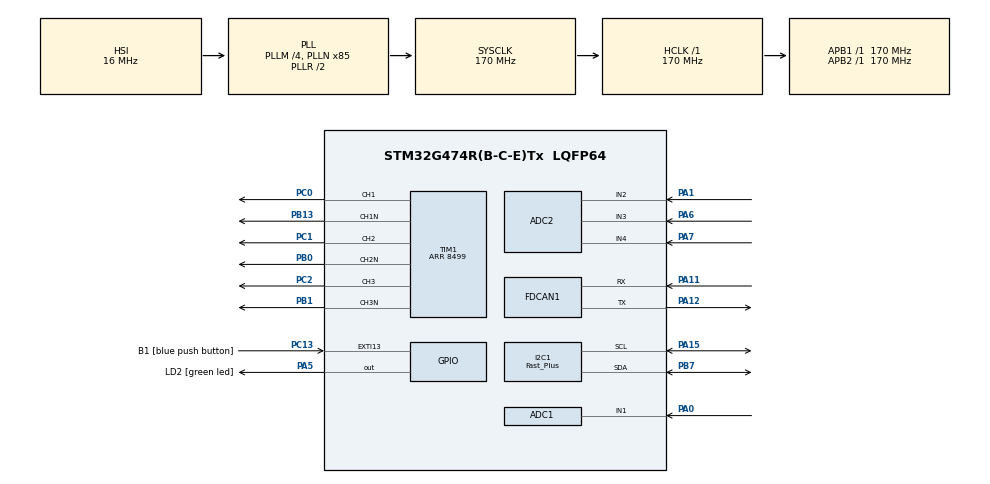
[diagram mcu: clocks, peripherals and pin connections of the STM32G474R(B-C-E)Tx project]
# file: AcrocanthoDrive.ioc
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ADC1.EnableInjectedConversion=ENABLE
ADC1.EnableRegularConversion=DISABLE
ADC1.ExternalTrigInjecConv=ADC_EXTERNALTRIGINJEC_T1_TRGO
ADC1.InjNumberOfConversion=1
ADC1.InjectedChannel-1\#ChannelInjectedConversion=ADC_CHANNEL_1
ADC1.InjectedOffsetNumber-1\#ChannelInjectedConversion=ADC_OFFSET_NONE
ADC1.InjectedRank-1\#ChannelInjectedConversion=1
ADC1.InjectedSamplingTime-1\#ChannelInjectedConversion=ADC_SAMPLETIME_2CYCLES_5
ADC1.Mode=ADC_DUALMODE_INJECSIMULT
ADC1.Rank1_Channel=ADC_CHANNEL_1
ADC1.master=1
ADC2.EOCSelection=ADC_EOC_SEQ_CONV
ADC2.EnableInjectedConversion=ENABLE
ADC2.EnableRegularConversion=DISABLE
ADC2.InjNumberOfConversion=3
ADC2.InjectedChannel-3\#ChannelInjectedConversion=ADC_CHANNEL_2
ADC2.InjectedChannel-4\#ChannelInjectedConversion=ADC_CHANNEL_3
ADC2.InjectedChannel-5\#ChannelInjectedConversion=ADC_CHANNEL_4
ADC2.InjectedOffsetNumber-3\#ChannelInjectedConversion=ADC_OFFSET_NONE
ADC2.InjectedOffsetNumber-4\#ChannelInjectedConversion=ADC_OFFSET_NONE
ADC2.InjectedOffsetNumber-5\#ChannelInjectedConversion=ADC_OFFSET_NONE
ADC2.InjectedRank-3\#ChannelInjectedConversion=1
ADC2.InjectedRank-4\#ChannelInjectedConversion=2
ADC2.InjectedRank-5\#ChannelInjectedConversion=3
ADC2.InjectedSamplingTime-3\#ChannelInjectedConversion=ADC_SAMPLETIME_2CYCLES_5
ADC2.InjectedSamplingTime-4\#ChannelInjectedConversion=ADC_SAMPLETIME_2CYCLES_5
ADC2.InjectedSamplingTime-5\#ChannelInjectedConversion=ADC_SAMPLETIME_2CYCLES_5
ADC2.Mode=ADC_DUALMODE_INJECSIMULT
ADC2.Rank1_Channel=ADC_CHANNEL_2
ADC2.Rank2_Channel=ADC_CHANNEL_3
ADC2.Rank3_Channel=ADC_CHANNEL_4
Dma.I2C1_RX.0.Direction=DMA_PERIPH_TO_MEMORY
Dma.I2C1_RX.0.EventEnable=DISABLE
Dma.I2C1_RX.0.Instance=DMA1_Channel1
Dma.I2C1_RX.0.MemDataAlignment=DMA_MDATAALIGN_BYTE
Dma.I2C1_RX.0.MemInc=DMA_MINC_ENABLE
Dma.I2C1_RX.0.Mode=DMA_NORMAL
Dma.I2C1_RX.0.PeriphDataAlignment=DMA_PDATAALIGN_BYTE
Dma.I2C1_RX.0.PeriphInc=DMA_PINC_DISABLE
Dma.I2C1_RX.0.Polarity=HAL_DMAMUX_REQ_GEN_RISING
Dma.I2C1_RX.0.Priority=DMA_PRIORITY_LOW
Dma.I2C1_RX.0.RequestNumber=1
Dma.I2C1_RX.0.SignalID=NONE
Dma.I2C1_RX.0.SyncEnable=DISABLE
Dma.I2C1_RX.0.SyncPolarity=HAL_DMAMUX_SYNC_NO_EVENT
Dma.I2C1_RX.0.SyncRequestNumber=1
Dma.I2C1_RX.0.SyncSignalID=NONE
Dma.I2C1_TX.1.Direction=DMA_MEMORY_TO_PERIPH
Dma.I2C1_TX.1.EventEnable=DISABLE
Dma.I2C1_TX.1.Instance=DMA1_Channel2
Dma.I2C1_TX.1.MemDataAlignment=DMA_MDATAALIGN_BYTE
Dma.I2C1_TX.1.MemInc=DMA_MINC_ENABLE
Dma.I2C1_TX.1.Mode=DMA_NORMAL
Dma.I2C1_TX.1.PeriphDataAlignment=DMA_PDATAALIGN_BYTE
Dma.I2C1_TX.1.PeriphInc=DMA_PINC_DISABLE
Dma.I2C1_TX.1.Polarity=HAL_DMAMUX_REQ_GEN_RISING
Dma.I2C1_TX.1.Priority=DMA_PRIORITY_LOW
Dma.I2C1_TX.1.RequestNumber=1
Dma.I2C1_TX.1.SignalID=NONE
Dma.I2C1_TX.1.SyncEnable=DISABLE
Dma.I2C1_TX.1.SyncPolarity=HAL_DMAMUX_SYNC_NO_EVENT
Dma.I2C1_TX.1.SyncRequestNumber=1
Dma.I2C1_TX.1.SyncSignalID=NONE
Dma.Request0=I2C1_RX
Dma.Request1=I2C1_TX
FDCAN1.CalculateBaudRateNominal=499999
FDCAN1.CalculateTimeBitNominal=2000
FDCAN1.CalculateTimeQuantumNominal=29.411764705882355
FDCAN1.DataPrescaler=5
FDCAN1.DataSyncJumpWidth=4
FDCAN1.DataTimeSeg1=12
FDCAN1.DataTimeSeg2=4
FDCAN1.FrameFormat=FDCAN_FRAME_FD_BRS
FDCAN1.NominalPrescaler=5
FDCAN1.NominalSyncJumpWidth=11
FDCAN1.NominalTimeSeg1=56
FDCAN1.NominalTimeSeg2=11
FDCAN1.ProtocolException=ENABLE
I2C1.I2C_Speed_Mode=I2C_Fast_Plus
I2C1.Timing=0x4052060F
Mcu.Family=STM32G4
Mcu.Name=STM32G474R(B-C-E)Tx
Mcu.Package=LQFP64
NVIC.ADC1_2_IRQn=true\:0\:0\:false\:false\:true\:true\:true\:true
NVIC.DMA1_Channel1_IRQn=true\:0\:0\:false\:false\:true\:false\:true\:true
NVIC.DMA1_Channel2_IRQn=true\:0\:0\:false\:false\:true\:false\:true\:true
NVIC.EXTI15_10_IRQn=true\:0\:0\:false\:false\:true\:true\:true\:true
NVIC.FDCAN1_IT0_IRQn=true\:0\:0\:false\:false\:true\:true\:true\:true
NVIC.FDCAN1_IT1_IRQn=true\:0\:0\:false\:false\:true\:true\:true\:true
NVIC.I2C1_ER_IRQn=true\:0\:0\:false\:false\:true\:true\:true\:true
NVIC.I2C1_EV_IRQn=true\:0\:0\:false\:false\:true\:true\:true\:true
NVIC.PriorityGroup=NVIC_PRIORITYGROUP_4
PA0.Mode=IN1-Single-Ended
PA0.Signal=ADC1_IN1
PA1.Mode=IN2-Single-Ended
PA1.Signal=ADC2_IN2
PA11.Mode=FDCAN_Activate
PA11.Signal=FDCAN1_RX
PA12.Mode=FDCAN_Activate
PA12.Signal=FDCAN1_TX
PA13.GPIO_Label=T_SWDIO
PA13.Signal=SYS_JTMS-SWDIO
PA14.GPIO_Label=T_SWCLK
PA14.Signal=SYS_JTCK-SWCLK
PA15.Mode=I2C
PA15.Signal=I2C1_SCL
PA2.GPIO_Label=LPUART1_TX [STLINKV3E_VCP_RX]
PA2.Signal=LPUART1_TX
PA3.GPIO_Label=LPUART1_RX [STLINKV3E_VCP_TX]
PA3.Signal=LPUART1_RX
PA5.GPIO_Label=LD2 [green led]
PA5.Signal=GPIO_Output
PA6.Mode=IN3-Single-Ended
PA6.Signal=ADC2_IN3
PA7.Mode=IN4-Single-Ended
PA7.Signal=ADC2_IN4
PB0.Mode=PWM Generation2 CH2 CH2N
PB0.Signal=TIM1_CH2N
PB1.Mode=PWM Generation3 CH3 CH3N
PB1.Signal=TIM1_CH3N
PB13.Mode=PWM Generation1 CH1 CH1N
PB13.Signal=TIM1_CH1N
PB3.GPIO_Label=T_SWO
PB3.Signal=SYS_JTDO-SWO
PB7.Mode=I2C
PB7.Signal=I2C1_SDA
PC0.Signal=S_TIM1_CH1
PC1.Signal=S_TIM1_CH2
PC13.GPIO_Label=B1 [blue push button]
PC13.Signal=GPXTI13
PC14-OSC32_IN.GPIO_Label=RCC_OSC32_IN
PC14-OSC32_IN.Signal=RCC_OSC32_IN
PC15-OSC32_OUT.GPIO_Label=RCC_OSC32_OUT
PC15-OSC32_OUT.Signal=RCC_OSC32_OUT
PC2.Signal=S_TIM1_CH3
PF0-OSC_IN.GPIO_Label=RCC_OSC_IN
PF0-OSC_IN.Signal=RCC_OSC_IN
PF1-OSC_OUT.GPIO_Label=RCC_OSC_OUT
PF1-OSC_OUT.Signal=RCC_OSC_OUT
ProjectManager.HeapSize=0x200
ProjectManager.StackSize=0x400
ProjectManager.TargetToolchain=STM32CubeIDE
RCC.ADC12Freq_Value=170000000
RCC.ADC345Freq_Value=170000000
RCC.AHBFreq_Value=170000000
RCC.APB1Freq_Value=170000000
RCC.APB1TimFreq_Value=170000000
RCC.APB2Freq_Value=170000000
RCC.APB2TimFreq_Value=170000000
RCC.CortexFreq_Value=170000000
RCC.EXTERNAL_CLOCK_VALUE=12288000
RCC.HCLKFreq_Value=170000000
RCC.HSE_VALUE=24000000
RCC.HSI48_VALUE=48000000
RCC.HSI_VALUE=16000000
RCC.LSE_VALUE=32768
RCC.PLLM=RCC_PLLM_DIV4
RCC.PLLN=85
RCC.RTCClockSelection=RCC_RTCCLKSOURCE_LSE
RCC.SYSCLKFreq_VALUE=170000000
RCC.SYSCLKSource=RCC_SYSCLKSOURCE_PLLCLK
RCC.USBFreq_Value=170000000
RCC.VCOOutputFreq_Value=340000000
SH.S_TIM1_CH1.0=TIM1_CH1,PWM Generation1 CH1 CH1N
SH.S_TIM1_CH2.0=TIM1_CH2,PWM Generation2 CH2 CH2N
SH.S_TIM1_CH3.0=TIM1_CH3,PWM Generation3 CH3 CH3N
TIM1.AutoReloadPreload=TIM_AUTORELOAD_PRELOAD_ENABLE
TIM1.Channel-PWM\ Generation1\ CH1\ CH1N=TIM_CHANNEL_1
TIM1.Channel-PWM\ Generation2\ CH2\ CH2N=TIM_CHANNEL_2
TIM1.Channel-PWM\ Generation3\ CH3\ CH3N=TIM_CHANNEL_3
TIM1.CounterMode=TIM_COUNTERMODE_CENTERALIGNED1
TIM1.DeadTime=20
TIM1.DeadTimePreload=ENABLE
TIM1.PeriodNoDither=8499
TIM1.RepetitionCounter=1
TIM1.TIM_MasterOutputTrigger=TIM_TRGO_UPDATE
TIM1.TIM_MasterOutputTrigger2=TIM_TRGO2_UPDATE
TIM1.TIM_MasterSlaveMode=TIM_MASTERSLAVEMODE_ENABLE
VP_CORDIC_VS_CORDIC.Mode=CORDIC_Activate
VP_SYS_VS_DBSignals.Mode=DisableDeadBatterySignals
board=NUCLEO-G474RE

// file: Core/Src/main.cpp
/* USER CODE BEGIN Header */
/**
  ******************************************************************************
  * @file           : main.c
  * @brief          : Main program body
  ******************************************************************************
  * @attention
  *
  * Copyright (c) 2024 STMicroelectronics.
  * All rights reserved.
  *
  * This software is licensed under terms that can be found in the LICENSE file
  * in the root directory of this software component.
  * If no LICENSE file comes with this software, it is provided AS-IS.
  *
  ******************************************************************************
  */
/* USER CODE END Header */
#include "main.h"

/* USER CODE BEGIN Includes */
#include "user_math.h"
#include "ang.h"

/* USER CODE END Includes */

ADC_HandleTypeDef hadc1;
ADC_HandleTypeDef hadc2;

CORDIC_HandleTypeDef hcordic;

FDCAN_HandleTypeDef hfdcan1;

I2C_HandleTypeDef hi2c1;
DMA_HandleTypeDef hdma_i2c1_rx;
DMA_HandleTypeDef hdma_i2c1_tx;

TIM_HandleTypeDef htim1;

void SystemClock_Config(void);
static void MX_GPIO_Init(void);
static void MX_DMA_Init(void);
static void MX_TIM1_Init(void);
static void MX_ADC1_Init(void);
static void MX_ADC2_Init(void);
static void MX_FDCAN1_Init(void);
static void MX_I2C1_Init(void);
static void MX_CORDIC_Init(void);

int main(void)
{

  /* MCU Configuration--------------------------------------------------------*/

  /* Reset of all peripherals, Initializes the Flash interface and the Systick. */
  HAL_Init();

  /* Configure the system clock */
  SystemClock_Config();

  /* Initialize all configured peripherals */
  MX_GPIO_Init();
  MX_DMA_Init();
  MX_TIM1_Init();
  MX_ADC1_Init();
  MX_ADC2_Init();
  MX_FDCAN1_Init();
  MX_I2C1_Init();
  MX_CORDIC_Init();

  /* Infinite loop */
  /* USER CODE BEGIN WHILE */
  Acrocantho::Cordic cordic;
  float a;
  float b;

  Ang ang(hi2c1);

  while (1)
  {
    /* USER CODE END WHILE */
    Acrocantho::SinCos result = cordic.radians(Acrocantho::userpi);
    a = result.c;
    b = result.s;

    ang.read();

  }
}

void SystemClock_Config(void)
{
  RCC_OscInitTypeDef RCC_OscInitStruct = {0};
  RCC_ClkInitTypeDef RCC_ClkInitStruct = {0};

  /** Configure the main internal regulator output voltage
  */
  HAL_PWREx_ControlVoltageScaling(PWR_REGULATOR_VOLTAGE_SCALE1_BOOST);

  /** Initializes the RCC Oscillators according to the specified parameters
  * in the RCC_OscInitTypeDef structure.
  */
  RCC_OscInitStruct.OscillatorType = RCC_OSCILLATORTYPE_HSI;
  RCC_OscInitStruct.HSIState = RCC_HSI_ON;
  RCC_OscInitStruct.HSICalibrationValue = RCC_HSICALIBRATION_DEFAULT;
  RCC_OscInitStruct.PLL.PLLState = RCC_PLL_ON;
  RCC_OscInitStruct.PLL.PLLSource = RCC_PLLSOURCE_HSI;
  RCC_OscInitStruct.PLL.PLLM = RCC_PLLM_DIV4;
  RCC_OscInitStruct.PLL.PLLN = 85;
  RCC_OscInitStruct.PLL.PLLP = RCC_PLLP_DIV2;
  RCC_OscInitStruct.PLL.PLLQ = RCC_PLLQ_DIV2;
  RCC_OscInitStruct.PLL.PLLR = RCC_PLLR_DIV2;
  if (HAL_RCC_OscConfig(&RCC_OscInitStruct) != HAL_OK)
  {
    Error_Handler();
  }

  /** Initializes the CPU, AHB and APB buses clocks
  */
  RCC_ClkInitStruct.ClockType = RCC_CLOCKTYPE_HCLK|RCC_CLOCKTYPE_SYSCLK
                              |RCC_CLOCKTYPE_PCLK1|RCC_CLOCKTYPE_PCLK2;
  RCC_ClkInitStruct.SYSCLKSource = RCC_SYSCLKSOURCE_PLLCLK;
  RCC_ClkInitStruct.AHBCLKDivider = RCC_SYSCLK_DIV1;
  RCC_ClkInitStruct.APB1CLKDivider = RCC_HCLK_DIV1;
  RCC_ClkInitStruct.APB2CLKDivider = RCC_HCLK_DIV1;

  if (HAL_RCC_ClockConfig(&RCC_ClkInitStruct, FLASH_LATENCY_4) != HAL_OK)
  {
    Error_Handler();
  }
}

static void MX_ADC1_Init(void)
{

  ADC_MultiModeTypeDef multimode = {0};
  ADC_InjectionConfTypeDef sConfigInjected = {0};

  /** Common config
  */
  hadc1.Instance = ADC1;
  hadc1.Init.ClockPrescaler = ADC_CLOCK_SYNC_PCLK_DIV4;
  hadc1.Init.Resolution = ADC_RESOLUTION_12B;
  hadc1.Init.DataAlign = ADC_DATAALIGN_RIGHT;
  hadc1.Init.GainCompensation = 0;
  hadc1.Init.ScanConvMode = ADC_SCAN_DISABLE;
  hadc1.Init.EOCSelection = ADC_EOC_SINGLE_CONV;
  hadc1.Init.LowPowerAutoWait = DISABLE;
  hadc1.Init.ContinuousConvMode = DISABLE;
  hadc1.Init.NbrOfConversion = 1;
  hadc1.Init.DiscontinuousConvMode = DISABLE;
  hadc1.Init.DMAContinuousRequests = DISABLE;
  hadc1.Init.Overrun = ADC_OVR_DATA_PRESERVED;
  hadc1.Init.OversamplingMode = DISABLE;
  if (HAL_ADC_Init(&hadc1) != HAL_OK)
  {
    Error_Handler();
  }

  /** Configure the ADC multi-mode
  */
  multimode.Mode = ADC_DUALMODE_INJECSIMULT;
  multimode.DMAAccessMode = ADC_DMAACCESSMODE_DISABLED;
  multimode.TwoSamplingDelay = ADC_TWOSAMPLINGDELAY_1CYCLE;
  if (HAL_ADCEx_MultiModeConfigChannel(&hadc1, &multimode) != HAL_OK)
  {
    Error_Handler();
  }

  /** Configure Injected Channel
  */
  sConfigInjected.InjectedChannel = ADC_CHANNEL_1;
  sConfigInjected.InjectedRank = ADC_INJECTED_RANK_1;
  sConfigInjected.InjectedSamplingTime = ADC_SAMPLETIME_2CYCLES_5;
  sConfigInjected.InjectedSingleDiff = ADC_SINGLE_ENDED;
  sConfigInjected.InjectedOffsetNumber = ADC_OFFSET_NONE;
  sConfigInjected.InjectedOffset = 0;
  sConfigInjected.InjectedNbrOfConversion = 1;
  sConfigInjected.InjectedDiscontinuousConvMode = DISABLE;
  sConfigInjected.AutoInjectedConv = DISABLE;
  sConfigInjected.QueueInjectedContext = DISABLE;
  sConfigInjected.ExternalTrigInjecConv = ADC_EXTERNALTRIGINJEC_T1_TRGO;
  sConfigInjected.ExternalTrigInjecConvEdge = ADC_EXTERNALTRIGINJECCONV_EDGE_RISING;
  sConfigInjected.InjecOversamplingMode = DISABLE;
  if (HAL_ADCEx_InjectedConfigChannel(&hadc1, &sConfigInjected) != HAL_OK)
  {
    Error_Handler();
  }

}

static void MX_ADC2_Init(void)
{

  ADC_InjectionConfTypeDef sConfigInjected = {0};

  /** Common config
  */
  hadc2.Instance = ADC2;
  hadc2.Init.ClockPrescaler = ADC_CLOCK_SYNC_PCLK_DIV4;
  hadc2.Init.Resolution = ADC_RESOLUTION_12B;
  hadc2.Init.DataAlign = ADC_DATAALIGN_RIGHT;
  hadc2.Init.GainCompensation = 0;
  hadc2.Init.ScanConvMode = ADC_SCAN_ENABLE;
  hadc2.Init.EOCSelection = ADC_EOC_SEQ_CONV;
  hadc2.Init.LowPowerAutoWait = DISABLE;
  hadc2.Init.ContinuousConvMode = DISABLE;
  hadc2.Init.NbrOfConversion = 1;
  hadc2.Init.DiscontinuousConvMode = DISABLE;
  hadc2.Init.DMAContinuousRequests = DISABLE;
  hadc2.Init.Overrun = ADC_OVR_DATA_PRESERVED;
  hadc2.Init.OversamplingMode = DISABLE;
  if (HAL_ADC_Init(&hadc2) != HAL_OK)
  {
    Error_Handler();
  }

  /** Configure Injected Channel
  */
  sConfigInjected.InjectedChannel = ADC_CHANNEL_2;
  sConfigInjected.InjectedRank = ADC_INJECTED_RANK_1;
  sConfigInjected.InjectedSamplingTime = ADC_SAMPLETIME_2CYCLES_5;
  sConfigInjected.InjectedSingleDiff = ADC_SINGLE_ENDED;
  sConfigInjected.InjectedOffsetNumber = ADC_OFFSET_NONE;
  sConfigInjected.InjectedOffset = 0;
  sConfigInjected.InjectedNbrOfConversion = 3;
  sConfigInjected.InjectedDiscontinuousConvMode = DISABLE;
  sConfigInjected.AutoInjectedConv = DISABLE;
  sConfigInjected.QueueInjectedContext = DISABLE;
  sConfigInjected.InjecOversamplingMode = DISABLE;
  if (HAL_ADCEx_InjectedConfigChannel(&hadc2, &sConfigInjected) != HAL_OK)
  {
    Error_Handler();
  }

  /** Configure Injected Channel
  */
  sConfigInjected.InjectedChannel = ADC_CHANNEL_3;
  sConfigInjected.InjectedRank = ADC_INJECTED_RANK_2;
  if (HAL_ADCEx_InjectedConfigChannel(&hadc2, &sConfigInjected) != HAL_OK)
  {
    Error_Handler();
  }

  /** Configure Injected Channel
  */
  sConfigInjected.InjectedChannel = ADC_CHANNEL_4;
  sConfigInjected.InjectedRank = ADC_INJECTED_RANK_3;
  if (HAL_ADCEx_InjectedConfigChannel(&hadc2, &sConfigInjected) != HAL_OK)
  {
    Error_Handler();
  }

}

static void MX_CORDIC_Init(void)
{

  hcordic.Instance = CORDIC;
  if (HAL_CORDIC_Init(&hcordic) != HAL_OK)
  {
    Error_Handler();
  }

}

static void MX_FDCAN1_Init(void)
{

  hfdcan1.Instance = FDCAN1;
  hfdcan1.Init.ClockDivider = FDCAN_CLOCK_DIV1;
  hfdcan1.Init.FrameFormat = FDCAN_FRAME_FD_BRS;
  hfdcan1.Init.Mode = FDCAN_MODE_NORMAL;
  hfdcan1.Init.AutoRetransmission = DISABLE;
  hfdcan1.Init.TransmitPause = DISABLE;
  hfdcan1.Init.ProtocolException = ENABLE;
  hfdcan1.Init.NominalPrescaler = 5;
  hfdcan1.Init.NominalSyncJumpWidth = 11;
  hfdcan1.Init.NominalTimeSeg1 = 56;
  hfdcan1.Init.NominalTimeSeg2 = 11;
  hfdcan1.Init.DataPrescaler = 5;
  hfdcan1.Init.DataSyncJumpWidth = 4;
  hfdcan1.Init.DataTimeSeg1 = 12;
  hfdcan1.Init.DataTimeSeg2 = 4;
  hfdcan1.Init.StdFiltersNbr = 0;
  hfdcan1.Init.ExtFiltersNbr = 0;
  hfdcan1.Init.TxFifoQueueMode = FDCAN_TX_FIFO_OPERATION;
  if (HAL_FDCAN_Init(&hfdcan1) != HAL_OK)
  {
    Error_Handler();
  }

}

static void MX_I2C1_Init(void)
{

  hi2c1.Instance = I2C1;
  hi2c1.Init.Timing = 0x4052060F;
  hi2c1.Init.OwnAddress1 = 0;
  hi2c1.Init.AddressingMode = I2C_ADDRESSINGMODE_7BIT;
  hi2c1.Init.DualAddressMode = I2C_DUALADDRESS_DISABLE;
  hi2c1.Init.OwnAddress2 = 0;
  hi2c1.Init.OwnAddress2Masks = I2C_OA2_NOMASK;
  hi2c1.Init.GeneralCallMode = I2C_GENERALCALL_DISABLE;
  hi2c1.Init.NoStretchMode = I2C_NOSTRETCH_DISABLE;
  if (HAL_I2C_Init(&hi2c1) != HAL_OK)
  {
    Error_Handler();
  }

  /** Configure Analogue filter
  */
  if (HAL_I2CEx_ConfigAnalogFilter(&hi2c1, I2C_ANALOGFILTER_ENABLE) != HAL_OK)
  {
    Error_Handler();
  }

  /** Configure Digital filter
  */
  if (HAL_I2CEx_ConfigDigitalFilter(&hi2c1, 0) != HAL_OK)
  {
    Error_Handler();
  }

  /** I2C Fast mode Plus enable
  */
  HAL_I2CEx_EnableFastModePlus(I2C_FASTMODEPLUS_I2C1);

}

static void MX_TIM1_Init(void)
{

  TIM_MasterConfigTypeDef sMasterConfig = {0};
  TIM_OC_InitTypeDef sConfigOC = {0};
  TIM_BreakDeadTimeConfigTypeDef sBreakDeadTimeConfig = {0};

  htim1.Instance = TIM1;
  htim1.Init.Prescaler = 0;
  htim1.Init.CounterMode = TIM_COUNTERMODE_CENTERALIGNED1;
  htim1.Init.Period = 8499;
  htim1.Init.ClockDivision = TIM_CLOCKDIVISION_DIV1;
  htim1.Init.RepetitionCounter = 1;
  htim1.Init.AutoReloadPreload = TIM_AUTORELOAD_PRELOAD_ENABLE;
  if (HAL_TIM_PWM_Init(&htim1) != HAL_OK)
  {
    Error_Handler();
  }
  sMasterConfig.MasterOutputTrigger = TIM_TRGO_UPDATE;
  sMasterConfig.MasterOutputTrigger2 = TIM_TRGO2_UPDATE;
  sMasterConfig.MasterSlaveMode = TIM_MASTERSLAVEMODE_ENABLE;
  if (HAL_TIMEx_MasterConfigSynchronization(&htim1, &sMasterConfig) != HAL_OK)
  {
    Error_Handler();
  }
  sConfigOC.OCMode = TIM_OCMODE_PWM1;
  sConfigOC.Pulse = 0;
  sConfigOC.OCPolarity = TIM_OCPOLARITY_HIGH;
  sConfigOC.OCNPolarity = TIM_OCNPOLARITY_HIGH;
  sConfigOC.OCFastMode = TIM_OCFAST_DISABLE;
  sConfigOC.OCIdleState = TIM_OCIDLESTATE_RESET;
  sConfigOC.OCNIdleState = TIM_OCNIDLESTATE_RESET;
  if (HAL_TIM_PWM_ConfigChannel(&htim1, &sConfigOC, TIM_CHANNEL_1) != HAL_OK)
  {
    Error_Handler();
  }
  if (HAL_TIM_PWM_ConfigChannel(&htim1, &sConfigOC, TIM_CHANNEL_2) != HAL_OK)
  {
    Error_Handler();
  }
  if (HAL_TIM_PWM_ConfigChannel(&htim1, &sConfigOC, TIM_CHANNEL_3) != HAL_OK)
  {
    Error_Handler();
  }
  HAL_TIMEx_EnableDeadTimePreload(&htim1);
  sBreakDeadTimeConfig.OffStateRunMode = TIM_OSSR_DISABLE;
  sBreakDeadTimeConfig.OffStateIDLEMode = TIM_OSSI_DISABLE;
  sBreakDeadTimeConfig.LockLevel = TIM_LOCKLEVEL_OFF;
  sBreakDeadTimeConfig.DeadTime = 20;
  sBreakDeadTimeConfig.BreakState = TIM_BREAK_DISABLE;
  sBreakDeadTimeConfig.BreakPolarity = TIM_BREAKPOLARITY_HIGH;
  sBreakDeadTimeConfig.BreakFilter = 0;
  sBreakDeadTimeConfig.BreakAFMode = TIM_BREAK_AFMODE_INPUT;
  sBreakDeadTimeConfig.Break2State = TIM_BREAK2_DISABLE;
  sBreakDeadTimeConfig.Break2Polarity = TIM_BREAK2POLARITY_HIGH;
  sBreakDeadTimeConfig.Break2Filter = 0;
  sBreakDeadTimeConfig.Break2AFMode = TIM_BREAK_AFMODE_INPUT;
  sBreakDeadTimeConfig.AutomaticOutput = TIM_AUTOMATICOUTPUT_DISABLE;
  if (HAL_TIMEx_ConfigBreakDeadTime(&htim1, &sBreakDeadTimeConfig) != HAL_OK)
  {
    Error_Handler();
  }
  HAL_TIM_MspPostInit(&htim1);

}

static void MX_DMA_Init(void)
{

  /* DMA controller clock enable */
  __HAL_RCC_DMAMUX1_CLK_ENABLE();
  __HAL_RCC_DMA1_CLK_ENABLE();

  /* DMA interrupt init */
  /* DMA1_Channel1_IRQn interrupt configuration */
  HAL_NVIC_SetPriority(DMA1_Channel1_IRQn, 0, 0);
  HAL_NVIC_EnableIRQ(DMA1_Channel1_IRQn);
  /* DMA1_Channel2_IRQn interrupt configuration */
  HAL_NVIC_SetPriority(DMA1_Channel2_IRQn, 0, 0);
  HAL_NVIC_EnableIRQ(DMA1_Channel2_IRQn);

}

static void MX_GPIO_Init(void)
{
  GPIO_InitTypeDef GPIO_InitStruct = {0};

  /* GPIO Ports Clock Enable */
  __HAL_RCC_GPIOC_CLK_ENABLE();
  __HAL_RCC_GPIOF_CLK_ENABLE();
  __HAL_RCC_GPIOA_CLK_ENABLE();
  __HAL_RCC_GPIOB_CLK_ENABLE();

  /*Configure GPIO pin Output Level */
  HAL_GPIO_WritePin(LD2_GPIO_Port, LD2_Pin, GPIO_PIN_RESET);

  /*Configure GPIO pin : B1_Pin */
  GPIO_InitStruct.Pin = B1_Pin;
  GPIO_InitStruct.Mode = GPIO_MODE_IT_RISING;
  GPIO_InitStruct.Pull = GPIO_NOPULL;
  HAL_GPIO_Init(B1_GPIO_Port, &GPIO_InitStruct);

  /*Configure GPIO pins : LPUART1_TX_Pin LPUART1_RX_Pin */
  GPIO_InitStruct.Pin = LPUART1_TX_Pin|LPUART1_RX_Pin;
  GPIO_InitStruct.Mode = GPIO_MODE_AF_PP;
  GPIO_InitStruct.Pull = GPIO_NOPULL;
  GPIO_InitStruct.Speed = GPIO_SPEED_FREQ_LOW;
  GPIO_InitStruct.Alternate = GPIO_AF12_LPUART1;
  HAL_GPIO_Init(GPIOA, &GPIO_InitStruct);

  /*Configure GPIO pin : LD2_Pin */
  GPIO_InitStruct.Pin = LD2_Pin;
  GPIO_InitStruct.Mode = GPIO_MODE_OUTPUT_PP;
  GPIO_InitStruct.Pull = GPIO_NOPULL;
  GPIO_InitStruct.Speed = GPIO_SPEED_FREQ_LOW;
  HAL_GPIO_Init(LD2_GPIO_Port, &GPIO_InitStruct);

  /* EXTI interrupt init*/
  HAL_NVIC_SetPriority(EXTI15_10_IRQn, 0, 0);
  HAL_NVIC_EnableIRQ(EXTI15_10_IRQn);

}

void Error_Handler(void)
{
  __disable_irq();
  while (1)
  {
  }
}
